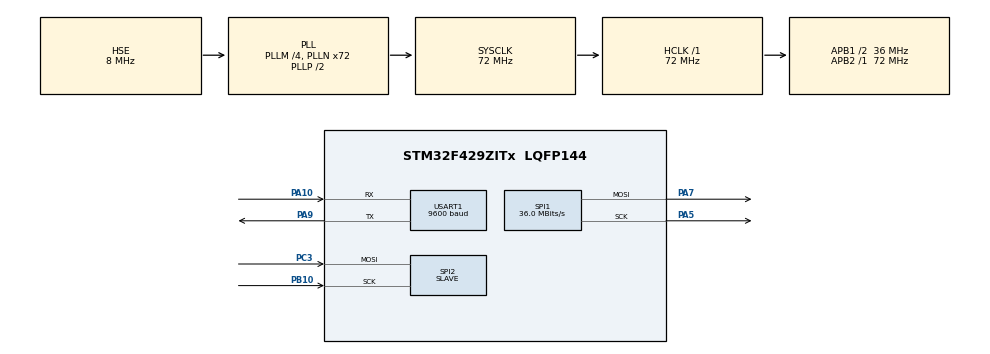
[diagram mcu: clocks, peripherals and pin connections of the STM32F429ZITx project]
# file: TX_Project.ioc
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Dma.Request0=SPI1_TX
Dma.Request1=SPI2_RX
Dma.SPI1_TX.0.Direction=DMA_MEMORY_TO_PERIPH
Dma.SPI1_TX.0.FIFOMode=DMA_FIFOMODE_DISABLE
Dma.SPI1_TX.0.Instance=DMA2_Stream3
Dma.SPI1_TX.0.MemDataAlignment=DMA_MDATAALIGN_BYTE
Dma.SPI1_TX.0.MemInc=DMA_MINC_ENABLE
Dma.SPI1_TX.0.Mode=DMA_NORMAL
Dma.SPI1_TX.0.PeriphDataAlignment=DMA_PDATAALIGN_BYTE
Dma.SPI1_TX.0.PeriphInc=DMA_PINC_DISABLE
Dma.SPI1_TX.0.Priority=DMA_PRIORITY_LOW
Dma.SPI2_RX.1.Direction=DMA_PERIPH_TO_MEMORY
Dma.SPI2_RX.1.FIFOMode=DMA_FIFOMODE_DISABLE
Dma.SPI2_RX.1.Instance=DMA1_Stream3
Dma.SPI2_RX.1.MemDataAlignment=DMA_MDATAALIGN_BYTE
Dma.SPI2_RX.1.MemInc=DMA_MINC_ENABLE
Dma.SPI2_RX.1.Mode=DMA_NORMAL
Dma.SPI2_RX.1.PeriphDataAlignment=DMA_PDATAALIGN_BYTE
Dma.SPI2_RX.1.PeriphInc=DMA_PINC_DISABLE
Dma.SPI2_RX.1.Priority=DMA_PRIORITY_LOW
Mcu.Family=STM32F4
Mcu.Name=STM32F429ZITx
Mcu.Package=LQFP144
NVIC.DMA1_Stream3_IRQn=true\:0\:0\:false\:false\:true\:false\:true
NVIC.DMA2_Stream3_IRQn=true\:0\:0\:false\:false\:true\:false\:true
NVIC.PriorityGroup=NVIC_PRIORITYGROUP_4
NVIC.USART1_IRQn=true\:0\:0\:false\:false\:true\:true\:true
PA10.Mode=Asynchronous
PA10.Signal=USART1_RX
PA13.Mode=Serial_Wire
PA13.Signal=SYS_JTMS-SWDIO
PA14.Mode=Serial_Wire
PA14.Signal=SYS_JTCK-SWCLK
PA5.Mode=TX_Only_Simplex_Unidirect_Master
PA5.Signal=SPI1_SCK
PA7.Mode=TX_Only_Simplex_Unidirect_Master
PA7.Signal=SPI1_MOSI
PA9.Mode=Asynchronous
PA9.Signal=USART1_TX
PB10.Mode=RX_Only_Simplex_Unidirect_Slave
PB10.Signal=SPI2_SCK
PC3.Mode=RX_Only_Simplex_Unidirect_Slave
PC3.Signal=SPI2_MOSI
PH0/OSC_IN.Mode=HSE-External-Oscillator
PH0/OSC_IN.Signal=RCC_OSC_IN
PH1/OSC_OUT.Mode=HSE-External-Oscillator
PH1/OSC_OUT.Signal=RCC_OSC_OUT
ProjectManager.HeapSize=0x200
ProjectManager.StackSize=0x400
ProjectManager.TargetToolchain=TrueSTUDIO
RCC.48MHZClocksFreq_Value=48000000
RCC.AHBFreq_Value=72000000
RCC.APB1CLKDivider=RCC_HCLK_DIV2
RCC.APB1Freq_Value=36000000
RCC.APB1TimFreq_Value=72000000
RCC.APB2Freq_Value=72000000
RCC.APB2TimFreq_Value=72000000
RCC.CortexFreq_Value=72000000
RCC.HCLKFreq_Value=72000000
RCC.HSE_VALUE=8000000
RCC.HSI_VALUE=16000000
RCC.LSE_VALUE=32768
RCC.PLLM=4
RCC.PLLN=72
RCC.PLLQ=3
RCC.PLLSAIN=50
RCC.PLLSourceVirtual=RCC_PLLSOURCE_HSE
RCC.SYSCLKFreq_VALUE=72000000
RCC.SYSCLKSource=RCC_SYSCLKSOURCE_PLLCLK
RCC.VCOOutputFreq_Value=144000000
SPI1.CalculateBaudRate=36.0 MBits/s
SPI1.Direction=SPI_DIRECTION_2LINES
SPI1.Mode=SPI_MODE_MASTER
SPI1.VirtualType=VM_MASTER
SPI2.Direction=SPI_DIRECTION_2LINES_RXONLY
SPI2.Mode=SPI_MODE_SLAVE
SPI2.VirtualType=VM_SLAVE
USART1.BaudRate=9600
USART1.VirtualMode=VM_ASYNC
board=STM32F429I-DISC1

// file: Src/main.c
/* USER CODE BEGIN Header */
/**
  ******************************************************************************
  * @file           : main.c
  * @brief          : Main program body
  ******************************************************************************
  * @attention
  *
  * <h2><center>&copy; Copyright (c) 2019 STMicroelectronics.
  * All rights reserved.</center></h2>
  *
  * This software component is licensed by ST under BSD 3-Clause license,
  * the "License"; You may not use this file except in compliance with the
  * License. You may obtain a copy of the License at:
  *                        opensource.org/licenses/BSD-3-Clause
  *
  ******************************************************************************
  */
/* USER CODE END Header */

#include "main.h"

SPI_HandleTypeDef hspi1;
SPI_HandleTypeDef hspi2;
DMA_HandleTypeDef hdma_spi1_tx;
DMA_HandleTypeDef hdma_spi2_rx;

UART_HandleTypeDef huart1;

/* USER CODE BEGIN PV */
uint16_t buffer_tx[10]= {0,1,2,3,4,5,6,7,8,9};
uint16_t buffer_rx[10];
/* USER CODE END PV */

void SystemClock_Config(void);
static void MX_GPIO_Init(void);
static void MX_DMA_Init(void);
static void MX_USART1_UART_Init(void);
static void MX_SPI1_Init(void);
static void MX_SPI2_Init(void);

/* USER CODE BEGIN 0 */
	void HAL_SPI_TxCpltCallback(SPI_HandleTypeDef *hspi)
	//void HAL_SPI_RxCpltCallback(SPI_HandleTypeDef *hspi)
   {
	   while(1);

   }
/* USER CODE END 0 */

int main(void)
{

  /* MCU Configuration--------------------------------------------------------*/

  /* Reset of all peripherals, Initializes the Flash interface and the Systick. */
  HAL_Init();

  /* Configure the system clock */
  SystemClock_Config();

  /* Initialize all configured peripherals */
  MX_GPIO_Init();
  MX_DMA_Init();
  MX_USART1_UART_Init();
  MX_SPI1_Init();
  MX_SPI2_Init();
  /* USER CODE BEGIN 2 */

 // HAL_SPI_Transmit(&hspi1,buffer_tx,10,10);

  //HAL_SPI_Receive(&hspi2,buffer_rx,10,10);

  /* USER CODE END 2 */

  /* Infinite loop */
  while (1)
  {
	  HAL_SPI_Transmit(&hspi1,buffer_tx,10,10);
  }
}

void SystemClock_Config(void)
{
  RCC_OscInitTypeDef RCC_OscInitStruct = {0};
  RCC_ClkInitTypeDef RCC_ClkInitStruct = {0};

  /** Configure the main internal regulator output voltage
  */
  __HAL_RCC_PWR_CLK_ENABLE();
  __HAL_PWR_VOLTAGESCALING_CONFIG(PWR_REGULATOR_VOLTAGE_SCALE3);
  /** Initializes the CPU, AHB and APB busses clocks
  */
  RCC_OscInitStruct.OscillatorType = RCC_OSCILLATORTYPE_HSE;
  RCC_OscInitStruct.HSEState = RCC_HSE_ON;
  RCC_OscInitStruct.PLL.PLLState = RCC_PLL_ON;
  RCC_OscInitStruct.PLL.PLLSource = RCC_PLLSOURCE_HSE;
  RCC_OscInitStruct.PLL.PLLM = 4;
  RCC_OscInitStruct.PLL.PLLN = 72;
  RCC_OscInitStruct.PLL.PLLP = RCC_PLLP_DIV2;
  RCC_OscInitStruct.PLL.PLLQ = 3;
  if (HAL_RCC_OscConfig(&RCC_OscInitStruct) != HAL_OK)
  {
    Error_Handler();
  }
  /** Initializes the CPU, AHB and APB busses clocks
  */
  RCC_ClkInitStruct.ClockType = RCC_CLOCKTYPE_HCLK|RCC_CLOCKTYPE_SYSCLK
                              |RCC_CLOCKTYPE_PCLK1|RCC_CLOCKTYPE_PCLK2;
  RCC_ClkInitStruct.SYSCLKSource = RCC_SYSCLKSOURCE_PLLCLK;
  RCC_ClkInitStruct.AHBCLKDivider = RCC_SYSCLK_DIV1;
  RCC_ClkInitStruct.APB1CLKDivider = RCC_HCLK_DIV2;
  RCC_ClkInitStruct.APB2CLKDivider = RCC_HCLK_DIV1;

  if (HAL_RCC_ClockConfig(&RCC_ClkInitStruct, FLASH_LATENCY_2) != HAL_OK)
  {
    Error_Handler();
  }
}

static void MX_SPI1_Init(void)
{

  /* SPI1 parameter configuration*/
  hspi1.Instance = SPI1;
  hspi1.Init.Mode = SPI_MODE_MASTER;
  hspi1.Init.Direction = SPI_DIRECTION_2LINES;
  hspi1.Init.DataSize = SPI_DATASIZE_8BIT;
  hspi1.Init.CLKPolarity = SPI_POLARITY_LOW;
  hspi1.Init.CLKPhase = SPI_PHASE_1EDGE;
  hspi1.Init.NSS = SPI_NSS_SOFT;
  hspi1.Init.BaudRatePrescaler = SPI_BAUDRATEPRESCALER_2;
  hspi1.Init.FirstBit = SPI_FIRSTBIT_MSB;
  hspi1.Init.TIMode = SPI_TIMODE_DISABLE;
  hspi1.Init.CRCCalculation = SPI_CRCCALCULATION_DISABLE;
  hspi1.Init.CRCPolynomial = 10;
  if (HAL_SPI_Init(&hspi1) != HAL_OK)
  {
    Error_Handler();
  }

}

static void MX_SPI2_Init(void)
{

  /* SPI2 parameter configuration*/
  hspi2.Instance = SPI2;
  hspi2.Init.Mode = SPI_MODE_SLAVE;
  hspi2.Init.Direction = SPI_DIRECTION_2LINES_RXONLY;
  hspi2.Init.DataSize = SPI_DATASIZE_8BIT;
  hspi2.Init.CLKPolarity = SPI_POLARITY_LOW;
  hspi2.Init.CLKPhase = SPI_PHASE_1EDGE;
  hspi2.Init.NSS = SPI_NSS_SOFT;
  hspi2.Init.FirstBit = SPI_FIRSTBIT_MSB;
  hspi2.Init.TIMode = SPI_TIMODE_DISABLE;
  hspi2.Init.CRCCalculation = SPI_CRCCALCULATION_DISABLE;
  hspi2.Init.CRCPolynomial = 10;
  if (HAL_SPI_Init(&hspi2) != HAL_OK)
  {
    Error_Handler();
  }

}

static void MX_USART1_UART_Init(void)
{

  huart1.Instance = USART1;
  huart1.Init.BaudRate = 9600;
  huart1.Init.WordLength = UART_WORDLENGTH_8B;
  huart1.Init.StopBits = UART_STOPBITS_1;
  huart1.Init.Parity = UART_PARITY_NONE;
  huart1.Init.Mode = UART_MODE_TX_RX;
  huart1.Init.HwFlowCtl = UART_HWCONTROL_NONE;
  huart1.Init.OverSampling = UART_OVERSAMPLING_16;
  if (HAL_UART_Init(&huart1) != HAL_OK)
  {
    Error_Handler();
  }

}

static void MX_DMA_Init(void)
{

  /* DMA controller clock enable */
  __HAL_RCC_DMA2_CLK_ENABLE();
  __HAL_RCC_DMA1_CLK_ENABLE();

  /* DMA interrupt init */
  /* DMA1_Stream3_IRQn interrupt configuration */
  HAL_NVIC_SetPriority(DMA1_Stream3_IRQn, 0, 0);
  HAL_NVIC_EnableIRQ(DMA1_Stream3_IRQn);
  /* DMA2_Stream3_IRQn interrupt configuration */
  HAL_NVIC_SetPriority(DMA2_Stream3_IRQn, 0, 0);
  HAL_NVIC_EnableIRQ(DMA2_Stream3_IRQn);

}

static void MX_GPIO_Init(void)
{

  /* GPIO Ports Clock Enable */
  __HAL_RCC_GPIOH_CLK_ENABLE();
  __HAL_RCC_GPIOC_CLK_ENABLE();
  __HAL_RCC_GPIOA_CLK_ENABLE();
  __HAL_RCC_GPIOB_CLK_ENABLE();

}

void Error_Handler(void)
{
}

/************************ (C) COPYRIGHT STMicroelectronics *****END OF FILE****/
